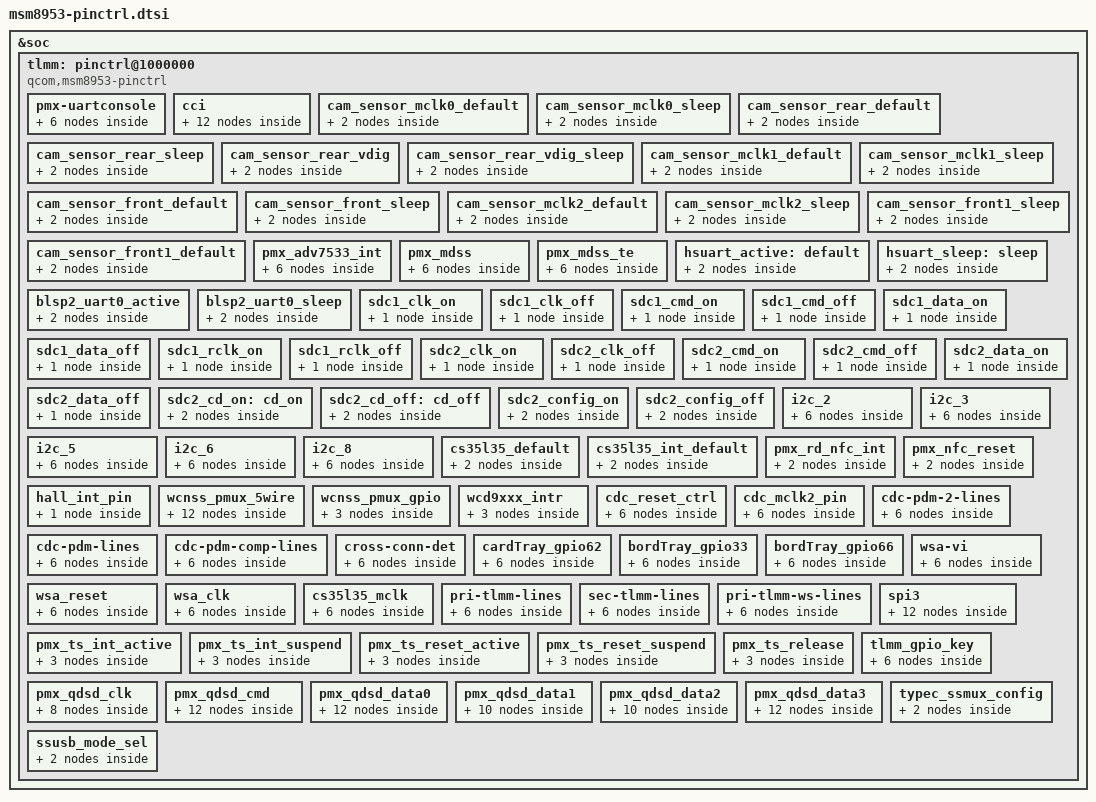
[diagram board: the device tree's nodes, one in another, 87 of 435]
/*
 * Copyright (c) 2015-2020, The Linux Foundation. All rights reserved.
 *
 * This program is free software; you can redistribute it and/or modify
 * it under the terms of the GNU General Public License version 2 and
 * only version 2 as published by the Free Software Foundation.
 *
 * This program is distributed in the hope that it will be useful,
 * but WITHOUT ANY WARRANTY; without even the implied warranty of
 * MERCHANTABILITY or FITNESS FOR A PARTICULAR PURPOSE.  See the
 * GNU General Public License for more details.
 */

&soc {
	tlmm: pinctrl@1000000 {
			compatible = "qcom,msm8953-pinctrl";
			reg = <0x1000000 0x300000>;
			interrupts = <0x00 0xd0 0x00>;
			gpio-controller;
			#gpio-cells = <0x02>;
			interrupt-controller;
			#interrupt-cells = <0x02>;
			linux,phandle = <0xbe>;
			phandle = <0xbe>;

			pmx-uartconsole {

				uart_console_active: uart_console_active {
					linux,phandle = <0xca>;
					phandle = <0xca>;

					mux {
						pins = "gpio4", "gpio5";
						function = "blsp_uart2";
					};

					config {
						pins = "gpio4", "gpio5";
						drive-strength = <0x02>;
						bias-disable;
					};
				};

				uart_console_sleep: uart_console_sleep {

					mux {
						pins = "gpio4", "gpio5";
						function = "blsp_uart2";
					};

					config {
						pins = "gpio4", "gpio5";
						drive-strength = <0x02>;
						bias-pull-down;
					};
				};
			};

			cci {

				cci0_active: cci0_active {
					linux,phandle = <0x189>;
					phandle = <0x189>;

					mux {
						pins = "gpio29", "gpio30";
						function = "cci_i2c";
					};

					config {
						pins = "gpio29", "gpio30";
						drive-strength = <0x02>;
						bias-disable;
					};
				};

				cci0_suspend: cci0_suspend {
					linux,phandle = <0x18b>;
					phandle = <0x18b>;

					mux {
						pins = "gpio29", "gpio30";
						function = "cci_i2c";
					};

					config {
						pins = "gpio29", "gpio30";
						drive-strength = <0x02>;
						bias-disable;
					};
				};

				cci1_active: cci1_active {
					linux,phandle = <0x18a>;
					phandle = <0x18a>;

					mux {
						pins = "gpio31", "gpio32";
						function = "cci_i2c";
					};

					config {
						pins = "gpio31", "gpio32";
						drive-strength = <0x02>;
						bias-disable;
					};
				};

				cci1_suspend: cci1_suspend {
					linux,phandle = <0x18c>;
					phandle = <0x18c>;

					mux {
						pins = "gpio31", "gpio32";
						function = "cci_i2c";
					};

					config {
						pins = "gpio31", "gpio32";
						drive-strength = <0x02>;
						bias-disable;
					};
				};
			};

			cam_sensor_mclk0_default: cam_sensor_mclk0_default {
				linux,phandle = <0x190>;
				phandle = <0x190>;

				mux {
					pins = "gpio26";
					function = "cam_mclk";
				};

				config {
					pins = "gpio26";
					bias-disable;
					drive-strength = <0x02>;
				};
			};

			cam_sensor_mclk0_sleep: cam_sensor_mclk0_sleep {
				linux,phandle = <0x193>;
				phandle = <0x193>;

				mux {
					pins = "gpio26";
					function = "cam_mclk";
				};

				config {
					pins = "gpio26";
					bias-pull-down;
					drive-strength = <0x02>;
				};
			};

			cam_sensor_rear_default: cam_sensor_rear_default {
				linux,phandle = <0x191>;
				phandle = <0x191>;

				mux {
					pins = "gpio40";
					function = "gpio";
				};

				config {
					pins = "gpio40";
					bias-disable;
					drive-strength = <0x02>;
				};
			};

			cam_sensor_rear_sleep: cam_sensor_rear_sleep {
				linux,phandle = <0x194>;
				phandle = <0x194>;

				mux {
					pins = "gpio40";
					function = "gpio";
				};

				config {
					pins = "gpio40";
					bias-disable;
					drive-strength = <0x02>;
				};
			};

			cam_sensor_rear_vdig: cam_sensor_rear_vdig {
				linux,phandle = <0x192>;
				phandle = <0x192>;

				mux {
					pins = "gpio128";
					function = "gpio";
				};

				config {
					pins = "gpio128";
					bias-disable;
					drive-strength = <0x02>;
				};
			};

			cam_sensor_rear_vdig_sleep: cam_sensor_rear_vdig_sleep {
				linux,phandle = <0x195>;
				phandle = <0x195>;

				mux {
					pins = "gpio128";
					function = "gpio";
				};

				config {
					pins = "gpio128";
					bias-disable;
					drive-strength = <0x02>;
				};
			};

			cam_sensor_mclk1_default: cam_sensor_mclk1_default {
				linux,phandle = <0x198>;
				phandle = <0x198>;

				mux {
					pins = "gpio27";
					function = "cam_mclk";
				};

				config {
					pins = "gpio27";
					bias-disable;
					drive-strength = <0x02>;
				};
			};

			cam_sensor_mclk1_sleep: cam_sensor_mclk1_sleep {
				linux,phandle = <0x19a>;
				phandle = <0x19a>;

				mux {
					pins = "gpio27";
					function = "cam_mclk";
				};

				config {
					pins = "gpio27";
					bias-pull-down;
					drive-strength = <0x02>;
				};
			};

			cam_sensor_front_default: cam_sensor_front_default {
				linux,phandle = <0x19d>;
				phandle = <0x19d>;

				mux {
					pins = "gpio129";
					function = "gpio";
				};

				config {
					pins = "gpio129";
					bias-disable;
					drive-strength = <0x02>;
				};
			};

			cam_sensor_front_sleep: cam_sensor_front_sleep {
				linux,phandle = <0x19f>;
				phandle = <0x19f>;

				mux {
					pins = "gpio129";
					function = "gpio";
				};

				config {
					pins = "gpio129";
					bias-disable;
					drive-strength = <0x02>;
				};
			};

			cam_sensor_mclk2_default: cam_sensor_mclk2_default {
				linux,phandle = <0x19c>;
				phandle = <0x19c>;

				mux {
					pins = "gpio28";
					function = "cam_mclk";
				};

				config {
					pins = "gpio28";
					bias-disable;
					drive-strength = <0x02>;
				};
			};

			cam_sensor_mclk2_sleep: cam_sensor_mclk2_sleep {
				linux,phandle = <0x19e>;
				phandle = <0x19e>;

				mux {
					pins = "gpio28";
					function = "cam_mclk";
				};

				config {
					pins = "gpio28";
					bias-pull-down;
					drive-strength = <0x02>;
				};
			};

			cam_sensor_front1_default: cam_sensor_front1_default {
				linux,phandle = <0x199>;
				phandle = <0x199>;

				mux {
					pins = "gpio131";
					function = "gpio";
				};

				config {
					pins = "gpio131";
					bias-disable;
					drive-strength = <0x02>;
				};
			};

			cam_sensor_front1_sleep: cam_sensor_front1_sleep {
				linux,phandle = <0x19b>;
				phandle = <0x19b>;

				mux {
					pins = "gpio131";
					function = "gpio";
				};

				config {
					pins = "gpio131";
					bias-disable;
					drive-strength = <0x02>;
				};
			};

			pmx_adv7533_int {

				adv7533_int_active: adv7533_int_active {
					linux,phandle = <0xdc>;
					phandle = <0xdc>;

					mux {
						pins = "gpio90";
						function = "gpio";
					};

					config {
						pins = "gpio90";
						drive-strength = <0x10>;
						bias-disable;
					};
				};

				adv7533_int_suspend: adv7533_int_suspend {
					linux,phandle = <0xdd>;
					phandle = <0xdd>;

					mux {
						pins = "gpio90";
						function = "gpio";
					};

					config {
						pins = "gpio90";
						drive-strength = <0x10>;
						bias-disable;
					};
				};
			};

			pmx_mdss {

				mdss_dsi_active: mdss_dsi_active {
					linux,phandle = <0x1b0>;
					phandle = <0x1b0>;

					mux {
						pins = "gpio61", "gpio59";
						function = "gpio";
					};

					config {
						pins = "gpio61", "gpio59";
						drive-strength = <0x08>;
						bias-disable = <0x00>;
						output-high;
					};
				};

				mdss_dsi_suspend: mdss_dsi_suspend {
					linux,phandle = <0x1b2>;
					phandle = <0x1b2>;

					mux {
						pins = "gpio61", "gpio59";
						function = "gpio";
					};

					config {
						pins = "gpio61", "gpio59";
						drive-strength = <0x02>;
						bias-disable = <0x00>;
						output-high;
					};
				};
			};

			pmx_mdss_te {

				mdss_te_active: mdss_te_active {
					linux,phandle = <0x1b1>;
					phandle = <0x1b1>;

					mux {
						pins = "gpio24";
						function = "mdp_vsync";
					};

					config {
						pins = "gpio24";
						drive-strength = <0x02>;
						bias-pull-down;
					};
				};

				mdss_te_suspend: mdss_te_suspend {
					linux,phandle = <0x1b3>;
					phandle = <0x1b3>;

					mux {
						pins = "gpio24";
						function = "mdp_vsync";
					};

					config {
						pins = "gpio24";
						drive-strength = <0x02>;
						bias-pull-down;
					};
				};
			};

			hsuart_active: default {
				linux,phandle = <0xcd>;
				phandle = <0xcd>;

				mux {
					pins = "gpio12", "gpio13", "gpio14", "gpio15";
					function = "blsp_uart4";
				};

				config {
					pins = "gpio12", "gpio13", "gpio14", "gpio15";
					drive-strength = <0x10>;
					bias-disable;
				};
			};

			hsuart_sleep: sleep {
				linux,phandle = <0xcc>;
				phandle = <0xcc>;

				mux {
					pins = "gpio12", "gpio13", "gpio14", "gpio15";
					function = "gpio";
				};

				config {
					pins = "gpio12", "gpio13", "gpio14", "gpio15";
					drive-strength = <0x02>;
					bias-disable;
				};
			};
            
            blsp2_uart0_active: blsp2_uart0_active {
			mux {
				pins = "gpio16", "gpio17", "gpio18", "gpio19";
				function = "blsp_uart5";
			};

			config {
				pins = "gpio16", "gpio17", "gpio18", "gpio19";
				drive-strength = <16>;
				bias-disable;
			};
		};

		blsp2_uart0_sleep: blsp2_uart0_sleep {
			mux {
				pins = "gpio16", "gpio17", "gpio18", "gpio19";
				function = "gpio";
			};

			config {
				pins = "gpio16", "gpio17", "gpio18", "gpio19";
				drive-strength = <2>;
				bias-disable;
			};
		};

        sdc1_clk_on: sdc1_clk_on {
				linux,phandle = <0x10b>;
				phandle = <0x10b>;

				config {
					pins = "sdc1_clk";
					bias-disable;
					drive-strength = <0x10>;
				};
			};

			sdc1_clk_off: sdc1_clk_off {
				linux,phandle = <0x10f>;
				phandle = <0x10f>;

				config {
					pins = "sdc1_clk";
					bias-disable;
					drive-strength = <0x02>;
				};
			};

			sdc1_cmd_on: sdc1_cmd_on {
				linux,phandle = <0x10c>;
				phandle = <0x10c>;

				config {
					pins = "sdc1_cmd";
					bias-pull-up;
					drive-strength = <0x0a>;
				};
			};

			sdc1_cmd_off: sdc1_cmd_off {
				linux,phandle = <0x110>;
				phandle = <0x110>;

				config {
					pins = "sdc1_cmd";
					num-grp-pins = <0x01>;
					bias-pull-up;
					drive-strength = <0x02>;
				};
			};

			sdc1_data_on: sdc1_data_on {
				linux,phandle = <0x10d>;
				phandle = <0x10d>;

				config {
					pins = "sdc1_data";
					bias-pull-up;
					drive-strength = <0x0a>;
				};
			};

			sdc1_data_off: sdc1_data_off {
				linux,phandle = <0x111>;
				phandle = <0x111>;

				config {
					pins = "sdc1_data";
					bias-pull-up;
					drive-strength = <0x02>;
				};
			};

			sdc1_rclk_on: sdc1_rclk_on {
				linux,phandle = <0x10e>;
				phandle = <0x10e>;

				config {
					pins = "sdc1_rclk";
					bias-pull-down;
				};
			};

			sdc1_rclk_off: sdc1_rclk_off {
				linux,phandle = <0x112>;
				phandle = <0x112>;

				config {
					pins = "sdc1_rclk";
					bias-pull-down;
				};
			};

			sdc2_clk_on: sdc2_clk_on {
				linux,phandle = <0x113>;
				phandle = <0x113>;

				config {
					pins = "sdc2_clk";
					drive-strength = <0x10>;
					bias-disable;
				};
			};

			sdc2_clk_off: sdc2_clk_off {
				linux,phandle = <0x117>;
				phandle = <0x117>;

				config {
					pins = "sdc2_clk";
					bias-disable;
					drive-strength = <0x02>;
				};
			};

			sdc2_cmd_on: sdc2_cmd_on {
				linux,phandle = <0x114>;
				phandle = <0x114>;

				config {
					pins = "sdc2_cmd";
					bias-pull-up;
					drive-strength = <0x0a>;
				};
			};

			sdc2_cmd_off: sdc2_cmd_off {
				linux,phandle = <0x118>;
				phandle = <0x118>;

				config {
					pins = "sdc2_cmd";
					bias-pull-up;
					drive-strength = <0x02>;
				};
			};

			sdc2_data_on: sdc2_data_on {
				linux,phandle = <0x115>;
				phandle = <0x115>;

				config {
					pins = "sdc2_data";
					bias-pull-up;
					drive-strength = <0x0a>;
				};
			};

			sdc2_data_off: sdc2_data_off {
				linux,phandle = <0x119>;
				phandle = <0x119>;

				config {
					pins = "sdc2_data";
					bias-pull-up;
					drive-strength = <0x02>;
				};
			};

				sdc2_cd_on: cd_on {
					linux,phandle = <0x116>;
					phandle = <0x116>;

					mux {
						pins = "gpio133";
						function = "gpio";
					};

					config {
						pins = "gpio133";
						drive-strength = <0x02>;
						bias-pull-up;
					};
				};

				sdc2_cd_off: cd_off {

					mux {
						pins = "gpio133";
						function = "gpio";
					};

					config {
						pins = "gpio133";
						drive-strength = <0x02>;
						bias-disable;
					};
				};

			sdc2_config_on: sdc2_config_on {

				mux {
					pins = "gpio54", "gpio58";
					function = "gpio";
				};

				config {
					pins = "gpio54", "gpio58";
					drive-strength = <0x02>;
					bias-pull-up;
					input-enable;
				};
			};

			sdc2_config_off: sdc2_config_off {

				mux {
					pins = "gpio54", "gpio58";
					function = "gpio";
				};

				config {
					pins = "gpio54", "gpio58";
					drive-strength = <0x02>;
					bias-disable;
				};
			};

			i2c_2 {

				i2c_2_active: i2c_2_active {
					linux,phandle = <0xd9>;
					phandle = <0xd9>;

					mux {
						pins = "gpio6", "gpio7";
						function = "blsp_i2c2";
					};

					config {
						pins = "gpio6", "gpio7";
						drive-strength = <0x02>;
						bias-disable;
					};
				};

				i2c_2_sleep: i2c_2_sleep {
					linux,phandle = <0xda>;
					phandle = <0xda>;

					mux {
						pins = "gpio6", "gpio7";
						function = "gpio";
					};

					config {
						pins = "gpio6", "gpio7";
						drive-strength = <0x02>;
						bias-disable;
					};
				};
			};

			i2c_3 {

				i2c_3_active: i2c_3_active {
					linux,phandle = <0xe5>;
					phandle = <0xe5>;

					mux {
						pins = "gpio10", "gpio11";
						function = "blsp_i2c3";
					};

					config {
						pins = "gpio10", "gpio11";
						drive-strength = <0x02>;
						bias-disable;
					};
				};

				i2c_3_sleep: i2c_3_sleep {
					linux,phandle = <0xe6>;
					phandle = <0xe6>;

					mux {
						pins = "gpio10", "gpio11";
						function = "gpio";
					};

					config {
						pins = "gpio10", "gpio11";
						drive-strength = <0x02>;
						bias-disable;
					};
				};
			};

			i2c_5 {

				i2c_5_active: i2c_5_active {
					linux,phandle = <0xe7>;
					phandle = <0xe7>;

					mux {
						pins = "gpio18", "gpio19";
						function = "blsp_i2c5";
					};

					config {
						pins = "gpio18", "gpio19";
						drive-strength = <0x06>;
						bias-disable;
					};
				};

				i2c_5_sleep: i2c_5_sleep {
					linux,phandle = <0xe8>;
					phandle = <0xe8>;

					mux {
						pins = "gpio18", "gpio19";
						function = "blsp_i2c5";
					};

					config {
						pins = "gpio18", "gpio19";
						drive-strength = <0x06>;
						bias-disable;
					};
				};
			};

			i2c_6 {

				i2c_6_active: i2c_6_active {
					linux,phandle = <0xef>;
					phandle = <0xef>;

					mux {
						pins = "gpio22", "gpio23";
						function = "blsp_i2c6";
					};

					config {
						pins = "gpio22", "gpio23";
						drive-strength = <0x06>;
						bias-disable;
					};
				};

				i2c_6_sleep: i2c_6_sleep {
					linux,phandle = <0xf0>;
					phandle = <0xf0>;

					mux {
						pins = "gpio22", "gpio23";
						function = "blsp_i2c6";
					};

					config {
						pins = "gpio22", "gpio23";
						drive-strength = <0x06>;
						bias-disable;
					};
				};
			};

			i2c_8 {

				i2c_8_active: i2c_8_active {
					linux,phandle = <0xf1>;
					phandle = <0xf1>;

					mux {
						pins = "gpio98", "gpio99";
						function = "blsp_i2c8";
					};

					config {
						pins = "gpio98", "gpio99";
						drive-strength = <0x02>;
						bias-disable;
					};
				};

				i2c_8_sleep: i2c_8_sleep {
					linux,phandle = <0xf2>;
					phandle = <0xf2>;

					mux {
						pins = "gpio98", "gpio99";
						function = "gpio";
					};

					config {
						pins = "gpio98", "gpio99";
						drive-strength = <0x02>;
						bias-disable;
					};
				};
			};

			cs35l35_default {

				mux {
					pins = "gpio91";
					function = "gpio";
				};

				config {
					pins = "gpio91";
					output-high;
					bias-pull-up;
					drive-strength = <0x02>;
				};
			};

			cs35l35_int_default: cs35l35_int_default {

				mux {
					pins = "gpio90";
					function = "gpio";
				};

				config {
					pins = "gpio90";
					bias-pull-up;
					drive-strength = <0x02>;
					input-enable;
				};
			};

			pmx_rd_nfc_int {
				pins = "gpio17";
				qcom,pin-func = <0x00>;
				qcom,num-grp-pins = <0x01>;
				label = "pmx_nfc_int";

				nfc_int_active: active {
					drive-strength = <0x06>;
					bias-pull-up;
					linux,phandle = <0xeb>;
					phandle = <0xeb>;
				};

				nfc_int_suspend: suspend {
					drive-strength = <0x06>;
					bias-pull-up;
					linux,phandle = <0xed>;
					phandle = <0xed>;
				};
			};

			pmx_nfc_reset {
				pins = "gpio16";
				qcom,pin-func = <0x00>;
				qcom,num-grp-pins = <0x01>;
				label = "pmx_nfc_disable";

				nfc_disable_active: active {
					drive-strength = <0x06>;
					bias-pull-up;
					linux,phandle = <0xec>;
					phandle = <0xec>;
				};

				nfc_disable_suspend: suspend {
					drive-strength = <0x06>;
					bias-disable;
					linux,phandle = <0xee>;
					phandle = <0xee>;
				};
			};

			hall_int_pin {
				qcom,pins = "gpio13";
				qcom,pin-func = <0x00>;
				qcom,num-grp-pins = <0x01>;
				label = "hall-irq";

				hall_sensor_int_default {
					drive-strength = <0x06>;
					bias-pull-up;
				};
			};

			wcnss_pmux_5wire {

				wcnss_default: wcnss_default {
					linux,phandle = <0x102>;
					phandle = <0x102>;

					wcss_wlan2 {
						pins = "gpio76";
						function = "wcss_wlan2";
					};

					wcss_wlan1 {
						pins = "gpio77";
						function = "wcss_wlan1";
					};

					wcss_wlan0 {
						pins = "gpio78";
						function = "wcss_wlan0";
					};

					wcss_wlan {
						pins = "gpio79", "gpio80";
						function = "wcss_wlan";
					};

					config {
						pins = "gpio76", "gpio77", "gpio78", "gpio79", "gpio80";
						drive-strength = <0x06>;
						bias-pull-up;
					};
				};

				wcnss_sleep: wcnss_sleep {
					linux,phandle = <0x103>;
					phandle = <0x103>;

					wcss_wlan2 {
						pins = "gpio76";
						function = "wcss_wlan2";
					};

					wcss_wlan1 {
						pins = "gpio77";
						function = "wcss_wlan1";
					};

					wcss_wlan0 {
						pins = "gpio78";
						function = "wcss_wlan0";
					};

					wcss_wlan {
						pins = "gpio79", "gpio80";
						function = "wcss_wlan";
					};

					config {
						pins = "gpio76", "gpio77", "gpio78", "gpio79", "gpio80";
						drive-strength = <0x02>;
						bias-pull-down;
					};
				};
			};

			wcnss_pmux_gpio: wcnss_pmux_gpio {
			wcnss_gpio_default: wcnss_gpio_default {
					linux,phandle = <0x104>;
					phandle = <0x104>;

					mux {
						pins = "gpio76", "gpio77", "gpio78", "gpio79", "gpio80";
						function = "gpio";
					};

					config {
						pins = "gpio76", "gpio77", "gpio78", "gpio79", "gpio80";
						drive-strength = <0x06>;
						bias-pull-up;
					};
				};
			};

			wcd9xxx_intr {

				wcd_intr_default: wcd_intr_default {
					linux,phandle = <0x17d>;
					phandle = <0x17d>;

					mux {
						pins = "gpio73";
						function = "gpio";
					};

					config {
						pins = "gpio73";
						drive-strength = <0x02>;
						bias-pull-down;
						input-enable;
					};
				};
			};

			cdc_reset_ctrl {

				cdc_reset_sleep: cdc_reset_sleep {
					linux,phandle = <0x17f>;
					phandle = <0x17f>;

					mux {
						pins = "gpio67";
						function = "gpio";
					};

					config {
						pins = "gpio67";
						drive-strength = <0x10>;
						bias-disable;
						output-low;
					};
				};

				cdc_reset_active: cdc_reset_active {
					linux,phandle = <0x17e>;
					phandle = <0x17e>;

					mux {
						pins = "gpio67";
						function = "gpio";
					};

					config {
						pins = "gpio67";
						drive-strength = <0x10>;
						bias-pull-down;
						output-high;
					};
				};
			};

			cdc_mclk2_pin {

				cdc_mclk2_sleep: cdc_mclk2_sleep {
					linux,phandle = <0x180>;
					phandle = <0x180>;

					mux {
						pins = "gpio66";
						function = "pri_mi2s";
					};

					config {
						pins = "gpio66";
						drive-strength = <0x02>;
						bias-pull-down;
					};
				};

				cdc_mclk2_active: cdc_mclk2_active {
					linux,phandle = <0x181>;
					phandle = <0x181>;

					mux {
						pins = "gpio66";
						function = "pri_mi2s";
					};

					config {
						pins = "gpio66";
						drive-strength = <0x08>;
						bias-disable;
					};
				};
			};

			cdc-pdm-2-lines {

				cdc_pdm_lines_2_act: pdm_lines_2_on {
					linux,phandle = <0x143>;
					phandle = <0x143>;

					mux {
						pins = "gpio70", "gpio71", "gpio72";
						function = "cdc_pdm0";
					};

					config {
						pins = "gpio70", "gpio71", "gpio72";
						drive-strength = <0x08>;
					};
				};

				cdc_pdm_lines_2_sus: pdm_lines_2_off {
					linux,phandle = <0x13d>;
					phandle = <0x13d>;

					mux {
						pins = "gpio70", "gpio71", "gpio72";
						function = "cdc_pdm0";
					};

					config {
						pins = "gpio70", "gpio71", "gpio72";
						drive-strength = <0x02>;
						bias-disable;
					};
				};
			};

			cdc-pdm-lines {

				cdc_pdm_lines_act: pdm_lines_on {
					linux,phandle = <0x142>;
					phandle = <0x142>;

					mux {
						pins = "gpio69", "gpio73", "gpio74";
						function = "cdc_pdm0";
					};

					config {
						pins = "gpio69", "gpio73", "gpio74";
						drive-strength = <0x08>;
					};
				};

				cdc_pdm_lines_sus: pdm_lines_off {
					linux,phandle = <0x13b>;
					phandle = <0x13b>;

					mux {
						pins = "gpio69", "gpio73", "gpio74";
						function = "cdc_pdm0";
					};

					config {
						pins = "gpio69", "gpio73", "gpio74";
						drive-strength = <0x02>;
						bias-disable;
					};
				};
			};

			cdc-pdm-comp-lines {

				cdc_pdm_comp_lines_act: pdm_comp_lines_on {

					mux {
						pins = "gpio67", "gpio68";
						function = "cdc_pdm0";
					};

					config {
						pins = "gpio67", "gpio68";
						drive-strength = <0x08>;
					};
				};

				cdc_pdm_comp_lines_sus: pdm_comp_lines_off {

					mux {
						pins = "gpio67", "gpio68";
						function = "cdc_pdm0";
					};

					config {
						pins = "gpio67", "gpio68";
						drive-strength = <0x02>;
						bias-disable;
					};
				};
			};

			cross-conn-det {

				cross_conn_det_act: lines_on {
					linux,phandle = <0x144>;
					phandle = <0x144>;

					mux {
						pins = "gpio63";
						function = "gpio";
					};

					config {
						pins = "gpio63";
						drive-strength = <0x08>;
						output-low;
						bias-pull-down;
					};
				};

				cross_conn_det_sus: lines_off {
					linux,phandle = <0x13e>;
					phandle = <0x13e>;

					mux {
						pins = "gpio63";
						function = "gpio";
					};

					config {
						pins = "gpio63";
						drive-strength = <0x02>;
						bias-pull-down;
					};
				};
			};

			cardTray_gpio62 {

				cardtray_gpio62_active {

					mux {
						pins = "gpio62";
						function = "gpio";
					};

					config {
						pins = "gpio62";
						bias-pull-down;
						drive-strength = <0x08>;
						input-enable;
					};
				};

				rf_read_gpio62_sus {

					mux {
						pins = "gpio62";
						function = "gpio";
					};

					config {
						pins = "gpio62";
						bias-pull-down;
						drive-strength = <0x08>;
						input-enable;
					};
				};
			};

			bordTray_gpio33 {

				bordtray_gpio33_active {

					mux {
						pins = "gpio33";
						function = "gpio";
					};

					config {
						pins = "gpio33";
						bias-pull-up;
						drive-strength = <0x08>;
						input-enable;
					};
				};

				bord_read_gpio33_sus {

					mux {
						pins = "gpio33";
						function = "gpio";
					};

					config {
						pins = "gpio33";
						bias-pull-up;
						drive-strength = <0x08>;
						input-enable;
					};
				};
			};

			bordTray_gpio66 {

				bordtray_gpio66_active {

					mux {
						pins = "gpio66";
						function = "gpio";
					};

					config {
						pins = "gpio66";
						bias-pull-up;
						drive-strength = <0x08>;
						input-enable;
					};
				};

				bord_read_gpio66_sus {

					mux {
						pins = "gpio66";
						function = "gpio";
					};

					config {
						pins = "gpio66";
						bias-pull-up;
						drive-strength = <0x08>;
						input-enable;
					};
				};
			};

			wsa-vi {

				wsa_vi_on: wsa_vi_on {
					linux,phandle = <0xe4>;
					phandle = <0xe4>;

					mux {
						pins = "gpio86", "gpio89";
						function = "wsa_io";
					};

					config {
						pins = "gpio86", "gpio89";
						drive-strength = <0x08>;
						bias-disable;
					};
				};

				wsa_vi_off: wsa_vi_off {
					linux,phandle = <0xe1>;
					phandle = <0xe1>;

					mux {
						pins = "gpio86", "gpio89";
						function = "wsa_io";
					};

					config {
						pins = "gpio86", "gpio89";
						drive-strength = <0x02>;
						bias-pull-down;
					};
				};
			};

			wsa_reset {

				wsa_reset_on: wsa_reset_on {
					linux,phandle = <0xe3>;
					phandle = <0xe3>;

					mux {
						pins = "gpio87";
						function = "gpio";
					};

					config {
						pins = "gpio87";
						drive-strength = <0x02>;
						output-high;
					};
				};

				wsa_reset_off: wsa_reset_off {
					linux,phandle = <0xe0>;
					phandle = <0xe0>;

					mux {
						pins = "gpio87";
						function = "gpio";
					};

					config {
						pins = "gpio87";
						drive-strength = <0x02>;
						output-low;
					};
				};
			};

			wsa_clk {

				wsa_clk_on: wsa_clk_on {
					linux,phandle = <0xe2>;
					phandle = <0xe2>;

					mux {
						pins = "gpio25";
						function = "pri_mi2s_mclk_a";
					};

					config {
						pins = "gpio25";
						drive-strength = <0x08>;
						output-high;
					};
				};

				wsa_clk_off: wsa_clk_off {
					linux,phandle = <0xdf>;
					phandle = <0xdf>;

					mux {
						pins = "gpio25";
						function = "pri_mi2s_mclk_a";
					};

					config {
						pins = "gpio25";
						drive-strength = <0x02>;
						output-low;
						bias-pull-down;
					};
				};
			};

			cs35l35_mclk: cs35l35_mclk {

				cs35l35_mclk_on: cs35l35_mclk_on {
					linux,phandle = <0x175>;
					phandle = <0x175>;

					mux {
						pins = "gpio25";
						function = "sec_mi2s_mclk_a";
					};

					config {
						pins = "gpio25";
						drive-strength = <0x08>;
						output-high;
					};
				};

				cs35l35_mclk_off: cs35l35_mclk_off {
					linux,phandle = <0x147>;
					phandle = <0x147>;

					mux {
						pins = "gpio25";
						function = "sec_mi2s_mclk_a";
					};

					config {
						pins = "gpio25";
						drive-strength = <0x02>;
						output-low;
						bias-pull-down;
					};
				};
			};

			pri-tlmm-lines {

				pri_tlmm_lines_act: pri_tlmm_lines_act {
					linux,phandle = <0x145>;
					phandle = <0x145>;

					mux {
						pins = "gpio91", "gpio93";
						function = "pri_mi2s";
					};

					config {
						pins = "gpio91", "gpio93";
						drive-strength = <0x08>;
					};
				};

				pri_tlmm_lines_sus: pri_tlmm_lines_sus {
					linux,phandle = <0x13f>;
					phandle = <0x13f>;

					mux {
						pins = "gpio91", "gpio93";
						function = "pri_mi2s";
					};

					config {
						pins = "gpio91", "gpio93";
						drive-strength = <0x02>;
						bias-pull-down;
					};
				};
			};

			sec-tlmm-lines {

				sec_tlmm_lines_act: sec_tlmm_lines_act {
					linux,phandle = <0x16e>;
					phandle = <0x16e>;

					mux {
						pins = "gpio135", "gpio136", "gpio137", "gpio138";
						function = "sec_mi2s";
					};

					config {
						pins = "gpio135", "gpio136", "gpio137", "gpio138";
						drive-strength = <0x08>;
					};
				};

				sec_tlmm_lines_sus: sec_tlmm_lines_sus {
					linux,phandle = <0x13c>;
					phandle = <0x13c>;

					mux {
						pins = "gpio135", "gpio136", "gpio137", "gpio138";
						function = "sec_mi2s";
					};

					config {
						pins = "gpio135", "gpio136", "gpio137", "gpio138";
						drive-strength = <0x02>;
						bias-disable;
					};
				};
			};

			pri-tlmm-ws-lines {

				pri_tlmm_ws_act: pri_tlmm_ws_act {
					linux,phandle = <0x146>;
					phandle = <0x146>;

					mux {
						pins = "gpio92";
						function = "pri_mi2s_ws";
					};

					config {
						pins = "gpio92";
						drive-strength = <0x08>;
					};
				};

				pri_tlmm_ws_sus: pri_tlmm_ws_sus {
					linux,phandle = <0x140>;
					phandle = <0x140>;

					mux {
						pins = "gpio92";
						function = "pri_mi2s_ws";
					};

					config {
						pins = "gpio92";
						drive-strength = <0x02>;
						bias-pull-down;
					};
				};
			};

			spi3 {

				spi3_default: spi3_default {
					linux,phandle = <0xce>;
					phandle = <0xce>;

					mux {
						pins = "gpio8", "gpio9", "gpio11";
						function = "blsp_spi3";
					};

					config {
						pins = "gpio8", "gpio9", "gpio11";
						drive-strength = <0x0c>;
						bias-disable = <0x00>;
					};
				};

				spi3_sleep: spi3_sleep {
					linux,phandle = <0xd0>;
					phandle = <0xd0>;

					mux {
						pins = "gpio8", "gpio9", "gpio11";
						function = "gpio";
					};

					config {
						pins = "gpio8", "gpio9", "gpio11";
						drive-strength = <0x02>;
						bias-pull-down;
					};
				};

				spi3_cs0_active: cs0_active {
					linux,phandle = <0xcf>;
					phandle = <0xcf>;

					mux {
						pins = "gpio10";
						function = "blsp_spi3";
					};

					config {
						pins = "gpio10";
						drive-strength = <0x02>;
						bias-disable = <0x00>;
					};
				};

				spi3_cs0_sleep: cs0_sleep {
					linux,phandle = <0xd1>;
					phandle = <0xd1>;

					mux {
						pins = "gpio10";
						function = "gpio";
					};

					config {
						pins = "gpio10";
						drive-strength = <0x02>;
						bias-disable = <0x00>;
					};
				};
			};

			pmx_ts_int_active {

				ts_int_active: ts_int_active {
					linux,phandle = <0xd4>;
					phandle = <0xd4>;

					mux {
						pins = "gpio65";
						function = "gpio";
					};

					config {
						pins = "gpio65";
						drive-strength = <0x08>;
						bias-pull-up;
					};
				};
			};

			pmx_ts_int_suspend {

				ts_int_suspend: ts_int_suspend {
					linux,phandle = <0xd6>;
					phandle = <0xd6>;

					mux {
						pins = "gpio65";
						function = "gpio";
					};

					config {
						pins = "gpio65";
						drive-strength = <0x02>;
						bias-pull-down;
					};
				};
			};

			pmx_ts_reset_active {

				ts_reset_active: ts_reset_active {
					linux,phandle = <0xd5>;
					phandle = <0xd5>;

					mux {
						pins = "gpio64";
						function = "gpio";
					};

					config {
						pins = "gpio64";
						drive-strength = <0x08>;
						bias-pull-up;
					};
				};
			};

			pmx_ts_reset_suspend {

				ts_reset_suspend: ts_reset_suspend {
					linux,phandle = <0xd7>;
					phandle = <0xd7>;

					mux {
						pins = "gpio64";
						function = "gpio";
					};

					config {
						pins = "gpio64";
						drive-strength = <0x02>;
						bias-pull-down;
					};
				};
			};

			pmx_ts_release {

				ts_release: ts_release {
					linux,phandle = <0xd8>;
					phandle = <0xd8>;

					mux {
						pins = "gpio65", "gpio64";
						function = "gpio";
					};

					config {
						pins = "gpio65", "gpio64";
						drive-strength = <0x02>;
						bias-pull-down;
					};
				};
			};

			tlmm_gpio_key {

				gpio_key_active: gpio_key_active {
					linux,phandle = <0x1bc>;
					phandle = <0x1bc>;

					mux {
						pins = "gpio85", "gpio86", "gpio87", "gpio141";
						function = "gpio";
					};

					config {
						pins = "gpio85", "gpio86", "gpio87", "gpio141";
						drive-strength = <0x02>;
						bias-pull-up;
					};
				};

				gpio_key_suspend: gpio_key_suspend {
					linux,phandle = <0x1bd>;
					phandle = <0x1bd>;

					mux {
						pins = "gpio85", "gpio86", "gpio87", "gpio141";
						function = "gpio";
					};

					config {
						pins = "gpio85", "gpio86", "gpio87", "gpio141";
						drive-strength = <0x02>;
						bias-pull-up;
					};
				};
			};

			pmx_qdsd_clk {

				qdsd_clk_sdcard: clk_sdcard {
					linux,phandle = <0x4a>;
					phandle = <0x4a>;

					config {
						pins = "qdsd_clk";
						bias-disable;
						drive-strength = <0x10>;
					};
				};

				qdsd_clk_trace: clk_trace {
					linux,phandle = <0x50>;
					phandle = <0x50>;

					config {
						pins = "qdsd_clk";
						bias-pull-down;
						drive-strength = <0x02>;
					};
				};

				qdsd_clk_swdtrc: clk_swdtrc {
					linux,phandle = <0x5b>;
					phandle = <0x5b>;

					config {
						pins = "qdsd_clk";
						bias-pull-down;
						drive-strength = <0x02>;
					};
				};

				qdsd_clk_spmi: clk_spmi {
					linux,phandle = <0x66>;
					phandle = <0x66>;

					config {
						pins = "qdsd_clk";
						bias-pull-down;
						drive-strength = <0x02>;
					};
				};
			};

			pmx_qdsd_cmd {

				qdsd_cmd_sdcard: cmd_sdcard {
					linux,phandle = <0x4b>;
					phandle = <0x4b>;

					config {
						pins = "qdsd_cmd";
						bias-pull-down;
						drive-strength = <0x08>;
					};
				};

				qdsd_cmd_trace: cmd_trace {
					linux,phandle = <0x51>;
					phandle = <0x51>;

					config {
						pins = "qdsd_cmd";
						bias-pull-down;
						drive-strength = <0x02>;
					};
				};

				qdsd_cmd_swduart: cmd_uart {
					linux,phandle = <0x56>;
					phandle = <0x56>;

					config {
						pins = "qdsd_cmd";
						bias-pull-up;
						drive-strength = <0x02>;
					};
				};

				qdsd_cmd_swdtrc: cmd_swdtrc {
					linux,phandle = <0x5c>;
					phandle = <0x5c>;

					config {
						pins = "qdsd_cmd";
						bias-pull-up;
						drive-strength = <0x02>;
					};
				};

				qdsd_cmd_jtag: cmd_jtag {
					linux,phandle = <0x61>;
					phandle = <0x61>;

					config {
						pins = "qdsd_cmd";
						bias-disable;
						drive-strength = <0x08>;
					};
				};

				qdsd_cmd_spmi: cmd_spmi {
					linux,phandle = <0x67>;
					phandle = <0x67>;

					config {
						pins = "qdsd_cmd";
						bias-pull-down;
						drive-strength = <0x0a>;
					};
				};
			};

			pmx_qdsd_data0 {

				qdsd_data0_sdcard: data0_sdcard {
					linux,phandle = <0x4c>;
					phandle = <0x4c>;

					config {
						pins = "qdsd_data0";
						bias-pull-down;
						drive-strength = <0x08>;
					};
				};

				qdsd_data0_trace: data0_trace {
					linux,phandle = <0x52>;
					phandle = <0x52>;

					config {
						pins = "qdsd_data0";
						bias-pull-down;
						drive-strength = <0x08>;
					};
				};

				qdsd_data0_swduart: data0_uart {
					linux,phandle = <0x57>;
					phandle = <0x57>;

					config {
						pins = "qdsd_data0";
						bias-pull-down;
						drive-strength = <0x02>;
					};
				};

				qdsd_data0_swdtrc: data0_swdtrc {
					linux,phandle = <0x5d>;
					phandle = <0x5d>;

					config {
						pins = "qdsd_data0";
						bias-pull-down;
						drive-strength = <0x02>;
					};
				};

				qdsd_data0_jtag: data0_jtag {
					linux,phandle = <0x62>;
					phandle = <0x62>;

					config {
						pins = "qdsd_data0";
						bias-pull-up;
						drive-strength = <0x02>;
					};
				};

				qdsd_data0_spmi: data0_spmi {
					linux,phandle = <0x68>;
					phandle = <0x68>;

					config {
						pins = "qdsd_data0";
						bias-pull-down;
						drive-strength = <0x02>;
					};
				};
			};

			pmx_qdsd_data1 {

				qdsd_data1_sdcard: data1_sdcard {
					linux,phandle = <0x4d>;
					phandle = <0x4d>;

					config {
						pins = "qdsd_data1";
						bias-pull-down;
						drive-strength = <0x08>;
					};
				};

				qdsd_data1_trace: data1_trace {
					linux,phandle = <0x53>;
					phandle = <0x53>;

					config {
						pins = "qdsd_data1";
						bias-pull-down;
						drive-strength = <0x08>;
					};
				};

				qdsd_data1_swduart: data1_uart {
					linux,phandle = <0x58>;
					phandle = <0x58>;

					config {
						pins = "qdsd_data1";
						bias-pull-down;
						drive-strength = <0x02>;
					};
				};

				qdsd_data1_swdtrc: data1_swdtrc {
					linux,phandle = <0x5e>;
					phandle = <0x5e>;

					config {
						pins = "qdsd_data1";
						bias-pull-down;
						drive-strength = <0x02>;
					};
				};

				qdsd_data1_jtag: data1_jtag {
					linux,phandle = <0x63>;
					phandle = <0x63>;

					config {
						pins = "qdsd_data1";
						bias-pull-down;
						drive-strength = <0x02>;
					};
				};
			};

			pmx_qdsd_data2 {

				qdsd_data2_sdcard: data2_sdcard {
					linux,phandle = <0x4e>;
					phandle = <0x4e>;

					config {
						pins = "qdsd_data2";
						bias-pull-down;
						drive-strength = <0x08>;
					};
				};

				qdsd_data2_trace: data2_trace {
					linux,phandle = <0x54>;
					phandle = <0x54>;

					config {
						pins = "qdsd_data2";
						bias-pull-down;
						drive-strength = <0x08>;
					};
				};

				qdsd_data2_swduart: data2_uart {
					linux,phandle = <0x59>;
					phandle = <0x59>;

					config {
						pins = "qdsd_data2";
						bias-pull-down;
						drive-strength = <0x02>;
					};
				};

				qdsd_data2_swdtrc: data2_swdtrc {
					linux,phandle = <0x5f>;
					phandle = <0x5f>;

					config {
						pins = "qdsd_data2";
						bias-pull-down;
						drive-strength = <0x02>;
					};
				};

				qdsd_data2_jtag: data2_jtag {
					linux,phandle = <0x64>;
					phandle = <0x64>;

					config {
						pins = "qdsd_data2";
						bias-pull-up;
						drive-strength = <0x08>;
					};
				};
			};

			pmx_qdsd_data3 {

				qdsd_data3_sdcard: data3_sdcard {
					linux,phandle = <0x4f>;
					phandle = <0x4f>;

					config {
						pins = "qdsd_data3";
						bias-pull-down;
						drive-strength = <0x08>;
					};
				};

				qdsd_data3_trace: data3_trace {
					linux,phandle = <0x55>;
					phandle = <0x55>;

					config {
						pins = "qdsd_data3";
						bias-pull-down;
						drive-strength = <0x08>;
					};
				};

				qdsd_data3_swduart: data3_uart {
					linux,phandle = <0x5a>;
					phandle = <0x5a>;

					config {
						pins = "qdsd_data3";
						bias-pull-up;
						drive-strength = <0x02>;
					};
				};

				qdsd_data3_swdtrc: data3_swdtrc {
					linux,phandle = <0x60>;
					phandle = <0x60>;

					config {
						pins = "qdsd_data3";
						bias-pull-up;
						drive-strength = <0x02>;
					};
				};

				qdsd_data3_jtag: data3_jtag {
					linux,phandle = <0x65>;
					phandle = <0x65>;

					config {
						pins = "qdsd_data3";
						bias-pull-up;
						drive-strength = <0x02>;
					};
				};

				qdsd_data3_spmi: data3_spmi {
					linux,phandle = <0x69>;
					phandle = <0x69>;

					config {
						pins = "qdsd_data3";
						bias-pull-down;
						drive-strength = <0x08>;
					};
				};
			};

			typec_ssmux_config: typec_ssmux_config {
				linux,phandle = <0x11c>;
				phandle = <0x11c>;

				mux {
					pins = "gpio139";
					function = "gpio";
				};

				config {
					pins = "gpio139";
					drive-strength = <0x02>;
					bias-disable;
				};
			};
            
            ssusb_mode_sel: ssusb_mode_sel {
			mux {
				pins = "gpio12";
				function = "gpio";
			};

			config {
				pins = "gpio12";
				drive-strength = <2>;
				bias-disable;
				input-enable;
			};
		};
		};
    };
